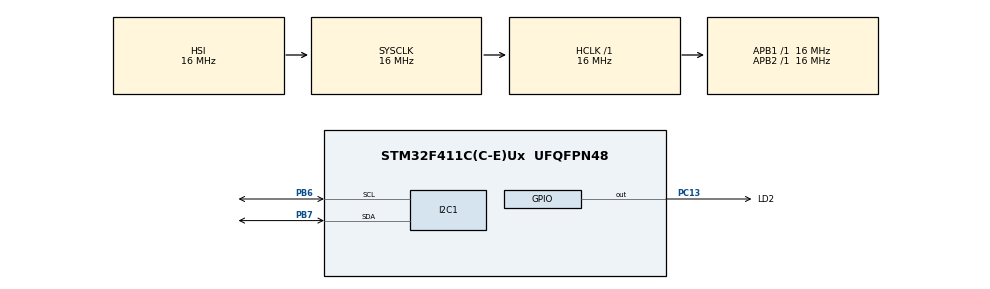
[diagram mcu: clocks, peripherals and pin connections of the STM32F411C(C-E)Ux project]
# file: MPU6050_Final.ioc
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Mcu.Family=STM32F4
Mcu.Name=STM32F411C(C-E)Ux
Mcu.Package=UFQFPN48
NVIC.PriorityGroup=NVIC_PRIORITYGROUP_4
NVIC.TIM1_UP_TIM10_IRQn=true\:0\:0\:false\:false\:true\:true\:true\:true
PA13.Mode=Serial_Wire
PA13.Signal=SYS_JTMS-SWDIO
PA14.Mode=Serial_Wire
PA14.Signal=SYS_JTCK-SWCLK
PB6.Mode=I2C
PB6.Signal=I2C1_SCL
PB7.Mode=I2C
PB7.Signal=I2C1_SDA
PC13-ANTI_TAMP.GPIO_Label=LD2
PC13-ANTI_TAMP.Signal=GPIO_Output
PC14-OSC32_IN.Mode=LSE-External-Oscillator
PC14-OSC32_IN.Signal=RCC_OSC32_IN
PC15-OSC32_OUT.Mode=LSE-External-Oscillator
PC15-OSC32_OUT.Signal=RCC_OSC32_OUT
PH0\ -\ OSC_IN.Mode=HSE-External-Oscillator
PH0\ -\ OSC_IN.Signal=RCC_OSC_IN
PH1\ -\ OSC_OUT.Mode=HSE-External-Oscillator
PH1\ -\ OSC_OUT.Signal=RCC_OSC_OUT
ProjectManager.HeapSize=0x200
ProjectManager.StackSize=0x400
ProjectManager.TargetToolchain=STM32CubeIDE
RCC.AHBFreq_Value=16000000
RCC.APB1Freq_Value=16000000
RCC.APB2Freq_Value=16000000
RCC.CortexFreq_Value=16000000
RCC.HSE_VALUE=25000000
RCC.HSI_VALUE=16000000
RCC.SYSCLKFreq_VALUE=16000000
RCC.VCOOutputFreq_Value=192000000
TIM1.Period=999
TIM1.Prescaler=16999
VP_TIM1_VS_ClockSourceINT.Mode=Internal
board=custom

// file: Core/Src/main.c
/* USER CODE BEGIN Header */
/**
  ******************************************************************************
  * @file           : main.c
  * @brief          : Main program body
  ******************************************************************************
  * @attention
  *
  * Copyright (c) 2025 STMicroelectronics.
  * All rights reserved.
  *
  * This software is licensed under terms that can be found in the LICENSE file
  * in the root directory of this software component.
  * If no LICENSE file comes with this software, it is provided AS-IS.
  *
  ******************************************************************************
  */
/* USER CODE END Header */
#include "main.h"
#include "i2c.h"
#include "tim.h"
#include "gpio.h"

/* USER CODE BEGIN Includes */
#include "MPU6050.h"
/* USER CODE END Includes */

/* USER CODE BEGIN PV */
// MPU6050
MPU6050_t MPU6050;
float Roll, Pitch, Yaw;
volatile uint8_t InterruptFlag = 0;

/* USER CODE END PV */

void SystemClock_Config(void);

int main(void)
{

  /* MCU Configuration--------------------------------------------------------*/

  /* Reset of all peripherals, Initializes the Flash interface and the Systick. */
  HAL_Init();

  /* Configure the system clock */
  SystemClock_Config();

  /* Initialize all configured peripherals */
  MX_GPIO_Init();
  MX_I2C1_Init();
  MX_TIM1_Init();

  /* Infinite loop */
  /* USER CODE BEGIN WHILE */
  while (1)
  {
	  if(InterruptFlag == 1)
	  {
		  InterruptFlag = 0;
		  MPU6050_Angle(&MPU6050, &Roll, &Pitch, &Yaw);
	  }
	  if(Roll < 5 && Roll > -5)
	  {
		  HAL_GPIO_WritePin(LD2_GPIO_Port, LD2_Pin, GPIO_PIN_SET);
	  }
	  HAL_GPIO_WritePin(LD2_GPIO_Port, LD2_Pin, GPIO_PIN_RESET);

    /* USER CODE END WHILE */

  }
}

void SystemClock_Config(void)
{
  RCC_OscInitTypeDef RCC_OscInitStruct = {0};
  RCC_ClkInitTypeDef RCC_ClkInitStruct = {0};

  /** Configure the main internal regulator output voltage
  */
  __HAL_RCC_PWR_CLK_ENABLE();
  __HAL_PWR_VOLTAGESCALING_CONFIG(PWR_REGULATOR_VOLTAGE_SCALE1);

  /** Initializes the RCC Oscillators according to the specified parameters
  * in the RCC_OscInitTypeDef structure.
  */
  RCC_OscInitStruct.OscillatorType = RCC_OSCILLATORTYPE_HSI;
  RCC_OscInitStruct.HSIState = RCC_HSI_ON;
  RCC_OscInitStruct.HSICalibrationValue = RCC_HSICALIBRATION_DEFAULT;
  RCC_OscInitStruct.PLL.PLLState = RCC_PLL_NONE;
  if (HAL_RCC_OscConfig(&RCC_OscInitStruct) != HAL_OK)
  {
    Error_Handler();
  }

  /** Initializes the CPU, AHB and APB buses clocks
  */
  RCC_ClkInitStruct.ClockType = RCC_CLOCKTYPE_HCLK|RCC_CLOCKTYPE_SYSCLK
                              |RCC_CLOCKTYPE_PCLK1|RCC_CLOCKTYPE_PCLK2;
  RCC_ClkInitStruct.SYSCLKSource = RCC_SYSCLKSOURCE_HSI;
  RCC_ClkInitStruct.AHBCLKDivider = RCC_SYSCLK_DIV1;
  RCC_ClkInitStruct.APB1CLKDivider = RCC_HCLK_DIV1;
  RCC_ClkInitStruct.APB2CLKDivider = RCC_HCLK_DIV1;

  if (HAL_RCC_ClockConfig(&RCC_ClkInitStruct, FLASH_LATENCY_0) != HAL_OK)
  {
    Error_Handler();
  }
}

/* USER CODE BEGIN 4 */
void HAL_TIM_IC_CaptureCallback(TIM_HandleTypeDef *htim)
{
	if(htim->Instance == TIM1)
	{
		InterruptFlag = 1;
	}
}
/* USER CODE END 4 */

void Error_Handler(void)
{
  __disable_irq();
  while (1)
  {
  }
}
